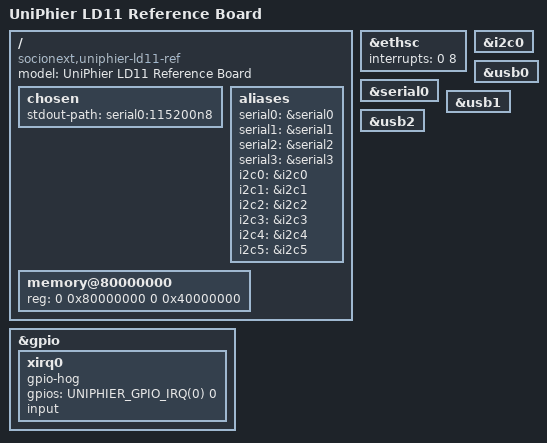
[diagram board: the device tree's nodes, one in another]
/*
 * Device Tree Source for UniPhier LD11 Reference Board
 *
 * Copyright (C) 2016 Socionext Inc.
 *   Author: Masahiro Yamada <yamada.masahiro@socionext.com>
 *
 * SPDX-License-Identifier: (GPL-2.0+ OR MIT)
 */

/dts-v1/;
#include "uniphier-ld11.dtsi"
#include "uniphier-ref-daughter.dtsi"
#include "uniphier-support-card.dtsi"

/ {
	model = "UniPhier LD11 Reference Board";
	compatible = "socionext,uniphier-ld11-ref", "socionext,uniphier-ld11";

	chosen {
		stdout-path = "serial0:115200n8";
	};

	aliases {
		serial0 = &serial0;
		serial1 = &serial1;
		serial2 = &serial2;
		serial3 = &serial3;
		i2c0 = &i2c0;
		i2c1 = &i2c1;
		i2c2 = &i2c2;
		i2c3 = &i2c3;
		i2c4 = &i2c4;
		i2c5 = &i2c5;
	};

	memory@80000000 {
		device_type = "memory";
		reg = <0 0x80000000 0 0x40000000>;
	};
};

&ethsc {
	interrupts = <0 8>;
};

&serial0 {
	status = "okay";
};

&gpio {
	xirq0 {
		gpio-hog;
		gpios = <UNIPHIER_GPIO_IRQ(0) 0>;
		input;
	};
};

&i2c0 {
	status = "okay";
};

&usb0 {
	status = "okay";
};

&usb1 {
	status = "okay";
};

&usb2 {
	status = "okay";
};
